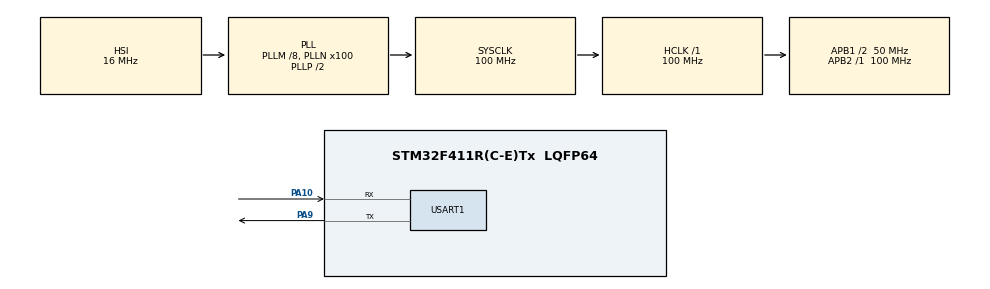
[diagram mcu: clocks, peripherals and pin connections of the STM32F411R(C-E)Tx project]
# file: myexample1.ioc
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Mcu.Family=STM32F4
Mcu.Name=STM32F411R(C-E)Tx
Mcu.Package=LQFP64
NVIC.PriorityGroup=NVIC_PRIORITYGROUP_4
PA10.Mode=Asynchronous
PA10.Signal=USART1_RX
PA9.Mode=Asynchronous
PA9.Signal=USART1_TX
PH0\ -\ OSC_IN.Mode=HSE-External-Oscillator
PH0\ -\ OSC_IN.Signal=RCC_OSC_IN
PH1\ -\ OSC_OUT.Mode=HSE-External-Oscillator
PH1\ -\ OSC_OUT.Signal=RCC_OSC_OUT
ProjectManager.HeapSize=0x200
ProjectManager.StackSize=0x400
ProjectManager.TargetToolchain=Makefile
RCC.48MHZClocksFreq_Value=50000000
RCC.AHBFreq_Value=100000000
RCC.APB1CLKDivider=RCC_HCLK_DIV2
RCC.APB1Freq_Value=50000000
RCC.APB1TimFreq_Value=100000000
RCC.APB2Freq_Value=100000000
RCC.APB2TimFreq_Value=100000000
RCC.CortexFreq_Value=100000000
RCC.HCLKFreq_Value=100000000
RCC.HSE_VALUE=8000000
RCC.HSI_VALUE=16000000
RCC.LSE_VALUE=32768
RCC.PLLM=8
RCC.PLLN=100
RCC.SYSCLKFreq_VALUE=100000000
RCC.SYSCLKSource=RCC_SYSCLKSOURCE_PLLCLK
RCC.VCOOutputFreq_Value=200000000
USART1.VirtualMode=VM_ASYNC
VP_IWDG_VS_IWDG.Mode=IWDG_Activate
VP_TIM1_VS_ClockSourceINT.Mode=Internal
VP_TIM2_VS_ClockSourceINT.Mode=Internal
VP_TIM3_VS_ClockSourceINT.Mode=Internal
board=custom

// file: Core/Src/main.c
/* USER CODE BEGIN Header */
/**
  ******************************************************************************
  * @file           : main.c
  * @brief          : Main program body
  ******************************************************************************
  * @attention
  *
  * Copyright (c) 2022 STMicroelectronics.
  * All rights reserved.
  *
  * This software is licensed under terms that can be found in the LICENSE file
  * in the root directory of this software component.
  * If no LICENSE file comes with this software, it is provided AS-IS.
  *
  ******************************************************************************
  */
/* USER CODE END Header */
#include "main.h"

IWDG_HandleTypeDef hiwdg;

TIM_HandleTypeDef htim1;
TIM_HandleTypeDef htim2;
TIM_HandleTypeDef htim3;

UART_HandleTypeDef huart1;

void SystemClock_Config(void);
static void MX_GPIO_Init(void);
static void MX_IWDG_Init(void);
static void MX_TIM1_Init(void);
static void MX_TIM2_Init(void);
static void MX_TIM3_Init(void);
static void MX_USART1_UART_Init(void);
/* USER CODE BEGIN PFP */
void my_led_init(void);
/* USER CODE END PFP */

int main(void)
{

  /* MCU Configuration--------------------------------------------------------*/

  /* Reset of all peripherals, Initializes the Flash interface and the Systick. */
  HAL_Init();

  /* Configure the system clock */
  SystemClock_Config();

  /* Initialize all configured peripherals */
  MX_GPIO_Init();
  MX_IWDG_Init();
  MX_TIM1_Init();
  MX_TIM2_Init();
  MX_TIM3_Init();
  MX_USART1_UART_Init();
  /* USER CODE BEGIN 2 */
  my_led_init();
  /* USER CODE END 2 */

  /* Infinite loop */
  while (1)
  {

  }
}

void SystemClock_Config(void)
{
  RCC_OscInitTypeDef RCC_OscInitStruct = {0};
  RCC_ClkInitTypeDef RCC_ClkInitStruct = {0};

  /** Configure the main internal regulator output voltage
  */
  __HAL_RCC_PWR_CLK_ENABLE();
  __HAL_PWR_VOLTAGESCALING_CONFIG(PWR_REGULATOR_VOLTAGE_SCALE1);
  /** Initializes the RCC Oscillators according to the specified parameters
  * in the RCC_OscInitTypeDef structure.
  */
  RCC_OscInitStruct.OscillatorType = RCC_OSCILLATORTYPE_HSI|RCC_OSCILLATORTYPE_LSI;
  RCC_OscInitStruct.HSIState = RCC_HSI_ON;
  RCC_OscInitStruct.HSICalibrationValue = RCC_HSICALIBRATION_DEFAULT;
  RCC_OscInitStruct.LSIState = RCC_LSI_ON;
  RCC_OscInitStruct.PLL.PLLState = RCC_PLL_ON;
  RCC_OscInitStruct.PLL.PLLSource = RCC_PLLSOURCE_HSI;
  RCC_OscInitStruct.PLL.PLLM = 8;
  RCC_OscInitStruct.PLL.PLLN = 100;
  RCC_OscInitStruct.PLL.PLLP = RCC_PLLP_DIV2;
  RCC_OscInitStruct.PLL.PLLQ = 4;
  if (HAL_RCC_OscConfig(&RCC_OscInitStruct) != HAL_OK)
  {
    Error_Handler();
  }
  /** Initializes the CPU, AHB and APB buses clocks
  */
  RCC_ClkInitStruct.ClockType = RCC_CLOCKTYPE_HCLK|RCC_CLOCKTYPE_SYSCLK
                              |RCC_CLOCKTYPE_PCLK1|RCC_CLOCKTYPE_PCLK2;
  RCC_ClkInitStruct.SYSCLKSource = RCC_SYSCLKSOURCE_PLLCLK;
  RCC_ClkInitStruct.AHBCLKDivider = RCC_SYSCLK_DIV1;
  RCC_ClkInitStruct.APB1CLKDivider = RCC_HCLK_DIV2;
  RCC_ClkInitStruct.APB2CLKDivider = RCC_HCLK_DIV1;

  if (HAL_RCC_ClockConfig(&RCC_ClkInitStruct, FLASH_LATENCY_3) != HAL_OK)
  {
    Error_Handler();
  }
}

static void MX_IWDG_Init(void)
{

  hiwdg.Instance = IWDG;
  hiwdg.Init.Prescaler = IWDG_PRESCALER_4;
  hiwdg.Init.Reload = 4095;
  if (HAL_IWDG_Init(&hiwdg) != HAL_OK)
  {
    Error_Handler();
  }

}

static void MX_TIM1_Init(void)
{

  TIM_ClockConfigTypeDef sClockSourceConfig = {0};
  TIM_MasterConfigTypeDef sMasterConfig = {0};

  htim1.Instance = TIM1;
  htim1.Init.Prescaler = 0;
  htim1.Init.CounterMode = TIM_COUNTERMODE_UP;
  htim1.Init.Period = 65535;
  htim1.Init.ClockDivision = TIM_CLOCKDIVISION_DIV1;
  htim1.Init.RepetitionCounter = 0;
  htim1.Init.AutoReloadPreload = TIM_AUTORELOAD_PRELOAD_DISABLE;
  if (HAL_TIM_Base_Init(&htim1) != HAL_OK)
  {
    Error_Handler();
  }
  sClockSourceConfig.ClockSource = TIM_CLOCKSOURCE_INTERNAL;
  if (HAL_TIM_ConfigClockSource(&htim1, &sClockSourceConfig) != HAL_OK)
  {
    Error_Handler();
  }
  sMasterConfig.MasterOutputTrigger = TIM_TRGO_RESET;
  sMasterConfig.MasterSlaveMode = TIM_MASTERSLAVEMODE_DISABLE;
  if (HAL_TIMEx_MasterConfigSynchronization(&htim1, &sMasterConfig) != HAL_OK)
  {
    Error_Handler();
  }

}

static void MX_TIM2_Init(void)
{

  TIM_ClockConfigTypeDef sClockSourceConfig = {0};
  TIM_MasterConfigTypeDef sMasterConfig = {0};

  htim2.Instance = TIM2;
  htim2.Init.Prescaler = 0;
  htim2.Init.CounterMode = TIM_COUNTERMODE_UP;
  htim2.Init.Period = 4294967295;
  htim2.Init.ClockDivision = TIM_CLOCKDIVISION_DIV1;
  htim2.Init.AutoReloadPreload = TIM_AUTORELOAD_PRELOAD_DISABLE;
  if (HAL_TIM_Base_Init(&htim2) != HAL_OK)
  {
    Error_Handler();
  }
  sClockSourceConfig.ClockSource = TIM_CLOCKSOURCE_INTERNAL;
  if (HAL_TIM_ConfigClockSource(&htim2, &sClockSourceConfig) != HAL_OK)
  {
    Error_Handler();
  }
  sMasterConfig.MasterOutputTrigger = TIM_TRGO_RESET;
  sMasterConfig.MasterSlaveMode = TIM_MASTERSLAVEMODE_DISABLE;
  if (HAL_TIMEx_MasterConfigSynchronization(&htim2, &sMasterConfig) != HAL_OK)
  {
    Error_Handler();
  }

}

static void MX_TIM3_Init(void)
{

  TIM_ClockConfigTypeDef sClockSourceConfig = {0};
  TIM_MasterConfigTypeDef sMasterConfig = {0};

  htim3.Instance = TIM3;
  htim3.Init.Prescaler = 0;
  htim3.Init.CounterMode = TIM_COUNTERMODE_UP;
  htim3.Init.Period = 65535;
  htim3.Init.ClockDivision = TIM_CLOCKDIVISION_DIV1;
  htim3.Init.AutoReloadPreload = TIM_AUTORELOAD_PRELOAD_DISABLE;
  if (HAL_TIM_Base_Init(&htim3) != HAL_OK)
  {
    Error_Handler();
  }
  sClockSourceConfig.ClockSource = TIM_CLOCKSOURCE_INTERNAL;
  if (HAL_TIM_ConfigClockSource(&htim3, &sClockSourceConfig) != HAL_OK)
  {
    Error_Handler();
  }
  sMasterConfig.MasterOutputTrigger = TIM_TRGO_RESET;
  sMasterConfig.MasterSlaveMode = TIM_MASTERSLAVEMODE_DISABLE;
  if (HAL_TIMEx_MasterConfigSynchronization(&htim3, &sMasterConfig) != HAL_OK)
  {
    Error_Handler();
  }

}

static void MX_USART1_UART_Init(void)
{

  huart1.Instance = USART1;
  huart1.Init.BaudRate = 115200;
  huart1.Init.WordLength = UART_WORDLENGTH_8B;
  huart1.Init.StopBits = UART_STOPBITS_1;
  huart1.Init.Parity = UART_PARITY_NONE;
  huart1.Init.Mode = UART_MODE_TX_RX;
  huart1.Init.HwFlowCtl = UART_HWCONTROL_NONE;
  huart1.Init.OverSampling = UART_OVERSAMPLING_16;
  if (HAL_UART_Init(&huart1) != HAL_OK)
  {
    Error_Handler();
  }

}

static void MX_GPIO_Init(void)
{

  /* GPIO Ports Clock Enable */
  __HAL_RCC_GPIOH_CLK_ENABLE();
  __HAL_RCC_GPIOA_CLK_ENABLE();

}

/* USER CODE BEGIN 4 */
void my_led_init(void)
{
    __HAL_RCC_GPIOA_CLK_ENABLE();

    GPIO_InitTypeDef GPIO_InitStruct = {0};

    GPIO_InitStruct.Pin = GPIO_PIN_5;
    GPIO_InitStruct.Mode = GPIO_MODE_OUTPUT_PP;
    GPIO_InitStruct.Pull = GPIO_NOPULL;
    GPIO_InitStruct.Speed = GPIO_SPEED_FREQ_VERY_HIGH;
    HAL_GPIO_Init(GPIOA, &GPIO_InitStruct);
    HAL_GPIO_WritePin(GPIOA,GPIO_PIN_5,GPIO_PIN_RESET);

}

/* USER CODE END 4 */

void Error_Handler(void)
{
  __disable_irq();
  while (1)
  {
  }
}
